# STM32H7S7xx register map
File version: 1.0
Registers are 32-bit, read-write, reset 0x0 unless marked. A register's access mark holds for its fields unless they carry their own. Offsets are from the block's base; [hi:lo] are bit positions; {n}, {i} and the like mark numbered series.

## GFXMMU
Base 0x52010000
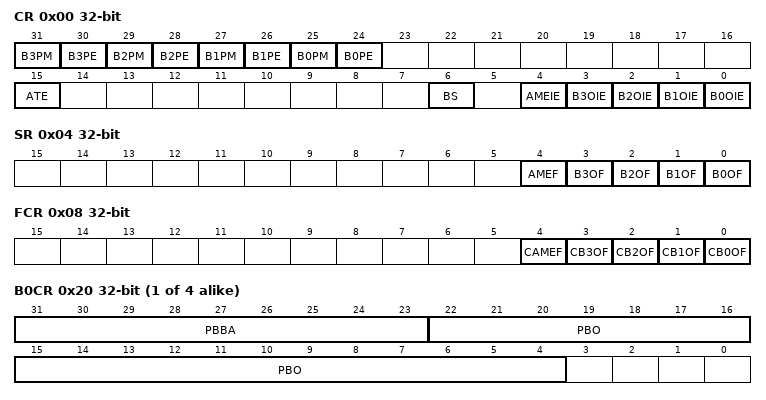
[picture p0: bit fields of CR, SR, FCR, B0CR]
0x00 CR — GFXMMU configuration register
  [31] B3PM — Buffer 0 packing mode
  [30] B3PE — Buffer 0 packing enable
  [29] B2PM — Buffer 0 packing mode
  [28] B2PE — Buffer 0 packing enable
  [27] B1PM — Buffer 1 packing mode
  [26] B1PE — Buffer 1 packing enable
  [25] B0PM — Buffer 0 packing mode
  [24] B0PE — Buffer 0 packing enable
  [15] ATE — Address translation enable
  [6] BS — Block size
  [4] AMEIE — AHB master error interrupt enable
  [n] B{n}OIE (n=0..3) — Buffer {n} overflow interrupt enable
0x04 SR — GFXMMU status register
  [4] AMEF — AXI master error flag
  [n] B{n}OF (n=0..3) — Buffer {n} overflow flag
0x08 FCR — GFXMMU flag clear register
  [4] CAMEF — Clear AHB master error flag
  [n] CB{n}OF (n=0..3) — Clear buffer {n} overflow flag
0x10 DVR — GFXMMU default value register
  [31:0] DV — DV[31:0] bits (Default value)
0x14 DAR — GFXMMU default alpha register
{0x20+4i} B{i}CR (i=0..3) — GFXMMU buffer {i} configuration register
  [31:23] PBBA — PBBA[31:23] bits (Physical buffer base address)
  [22:4] PBO — PB0[22:4] bits (Physical buffer offset)
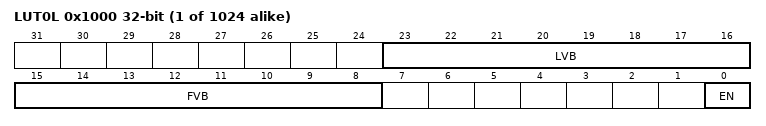
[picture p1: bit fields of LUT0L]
{0x1000+8i} LUT{i}L (i=0..1023) — GFXMMU LUT registers
  [23:16] LVB — LVB[7:0] bits (Last visible block)
  [15:8] FVB — FVB[7:0] bits (First visible block)
  [0] EN — Enable
{0x1004+8i} LUT{i}H (i=0..1023) — GFXMMU LUT registers
  [17:0] LO — LO[17:0] bits (Line offset)

## ICACHE — Instruction Cache
Base 0x52015000
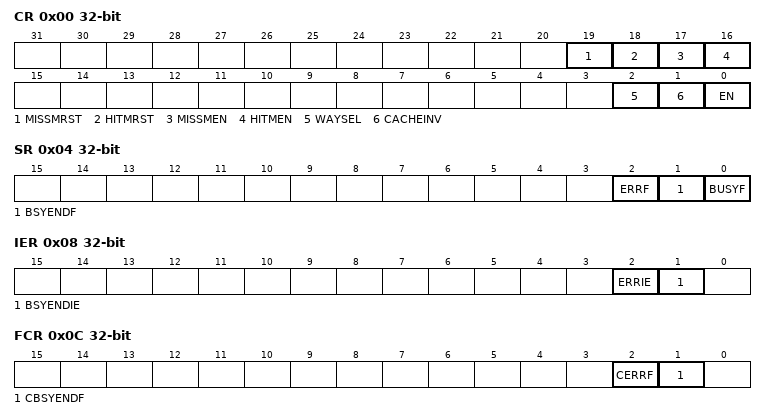
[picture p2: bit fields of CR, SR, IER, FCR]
0x00 CR — ICACHE control register
  [19] MISSMRST — Miss monitor reset
  [18] HITMRST — Hit monitor reset
  [17] MISSMEN — Miss monitor enable
  [16] HITMEN — Hit monitor enable
  [2] WAYSEL — Ways selection
    0=ICACHE_1WAY (1-way cache (direct mapped cache)); 1=ICACHE_4WAYS (4-ways set associative cache (default))
  [1] CACHEINV — Cache invalidation
  [0] EN — Enable
0x04 SR — ICACHE status register
  [2] ERRF — Cache error flag
  [1] BSYENDF — Busy end flag
  [0] BUSYF — Busy flag
0x08 IER — ICACHE interrupt enable register
  [2] ERRIE — Cache error interrupt enable
  [1] BSYENDIE — Busy end interrupt enable
0x0C FCR — ICACHE flag clear register
  [2] CERRF — Cache error flag clear
  [1] CBSYENDF — Busy end flag clear
0x10 HMONR — ICACHE hit monitor register
  [31:0] HITMON — Cache hit monitor register
0x14 MMONR — ICACHE miss monitor register
  [15:0] MISSMON — Cache miss monitor register

## EXTI — External Interrupt/Event Controller
Base 0x58000000
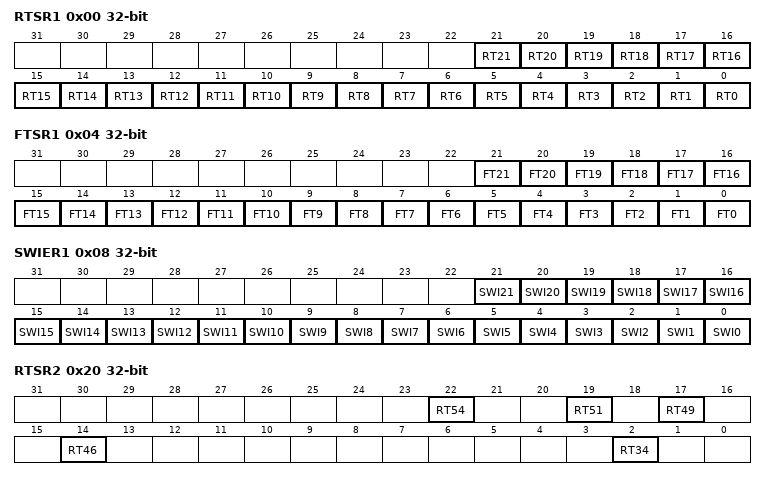
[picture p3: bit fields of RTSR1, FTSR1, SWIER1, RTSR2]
0x00 RTSR1 — EXTI Rising trigger selection register 1
  [n] RT{n} (n=0..21) — Rising trigger configuration for input line {n}
0x04 FTSR1 — EXTI Falling trigger selection register 1
  [n] FT{n} (n=0..21) — Falling trigger configuration for input line {n}
0x08 SWIER1 — EXTI Software interrupt event register 1
  [n] SWI{n} (n=0..21) — Software Interrupt on line {n}
0x20 RTSR2 — EXTI Rising trigger selection register 2
  [22] RT54 — Rising trigger configuration for input line 54
  [19] RT51 — Rising trigger configuration for input line 51
  [17] RT49 — Rising trigger configuration for input line 49
  [14] RT46 — Rising trigger configuration for input line 46
  [2] RT34 — Rising trigger configuration for input line 34
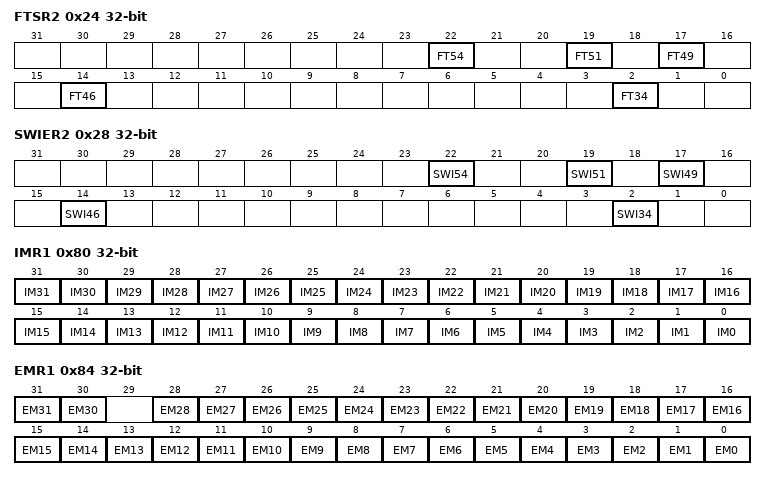
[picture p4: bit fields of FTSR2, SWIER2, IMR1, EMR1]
0x24 FTSR2 — EXTI Falling trigger selection register 2
  [22] FT54 — Falling trigger configuration for input line 54
  [19] FT51 — Falling trigger configuration for input line 51
  [17] FT49 — Falling trigger configuration for input line 49
  [14] FT46 — Falling trigger configuration for input line 46
  [2] FT34 — Falling trigger configuration for input line 34
0x28 SWIER2 — EXTI Software interrupt event register 2
  [22] SWI54 — Software Interrupt on line 54
  [19] SWI51 — Software Interrupt on line 51
  [17] SWI49 — Software Interrupt on line 49
  [14] SWI46 — Software Interrupt on line 46
  [2] SWI34 — Software Interrupt on line 34
0x80 IMR1 — EXTI Interrupt mask register 1
  [n] IM{n} (n=0..31) — Interrupt Mask on line {n}
0x84 EMR1 — EXTI Event mask register 1
  [31] EM31 — Event Mask on line 31
  [30] EM30 — Event Mask on line 30
  [n] EM{n} (n=0..28) — Event Mask on line {n}
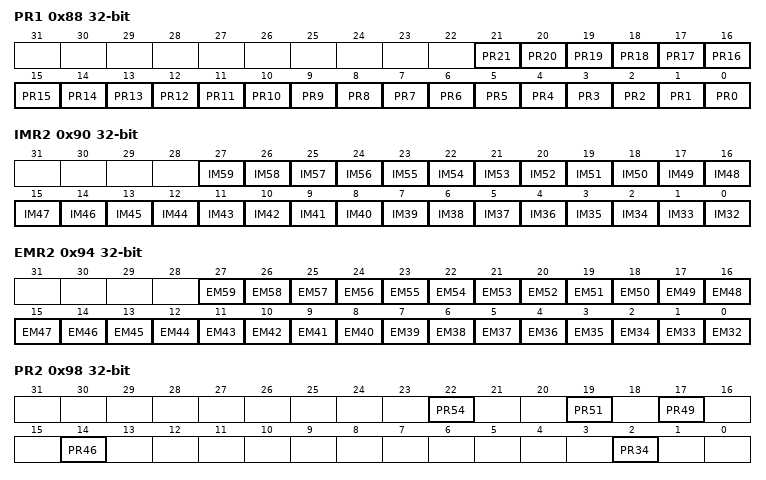
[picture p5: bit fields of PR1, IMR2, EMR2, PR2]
0x88 PR1 — EXTI Pending register 1
  [n] PR{n} (n=0..21) — Pending bit for line {n}
0x90 IMR2 — EXTI Interrupt mask register 2
  [n-32] IM{n} (n=32..59) — Interrupt Mask on line {n}
0x94 EMR2 — EXTI Event mask register 2
  [n-32] EM{n} (n=32..59) — Event Mask on line {n}
0x98 PR2 — EXTI Pending register 2
  [22] PR54 — Event Mask on line 54
  [19] PR51 — Event Mask on line 51
  [17] PR49 — Event Mask on line 49
  [14] PR46 — Event Mask on line 46
  [2] PR34 — Event Mask on line 34
0xA0 IMR3 — EXTI Interrupt mask register 3
  [13] IM77 — Interrupt Mask on line 77
0xA4 EMR3 — EXTI Event mask register 3
  [13] EM77 — Event Mask on line 77
